# MM32F3270 register map
File version: 3.01
CPU: CM3 r2p1, selectable endian, MPU, no FPU, 3 interrupt priority bits
Registers are 32-bit, read-write, reset 0x0 unless marked. A register's access mark holds for its fields unless they carry their own. Offsets are from the block's base; [hi:lo] are bit positions; lines under a group give offsets from that group; {n}, {i} and the like mark numbered series.

## CAN — Controller area network
Base 0x40006400
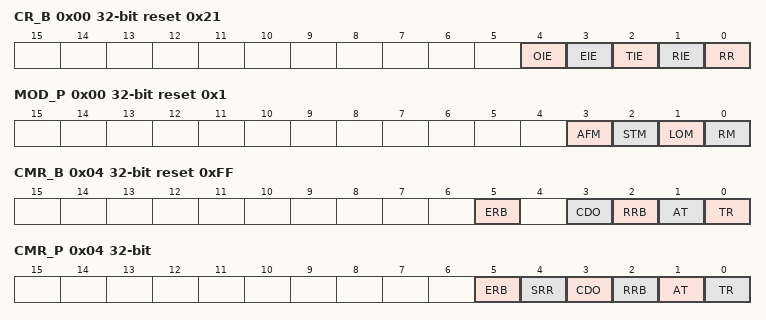
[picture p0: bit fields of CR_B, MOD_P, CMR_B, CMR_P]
0x00 CR_B reset 0x21 — Basic control register
  [4] OIE — Overflow interrupt enable
  [3] EIE — Error interrupt enable
  [2] TIE — Transmit interrupt enable
  [1] RIE — Receive interrupt enable
  [0] RR — Reset request
0x00 MOD_P reset 0x1 (alternate view of CR_B) — Peli Mode register
  [3] AFM — Acceptance filter mode
  [2] STM — Self test mode
  [1] LOM — Listen only mode
  [0] RM — Reset mode
0x04 CMR_B wo reset 0xFF — Basic Command register
  [5] ERB — Empty Rxbuffer
  [3] CDO — Clear data overrun
  [2] RRB — Release receive buffer
  [1] AT — Abort transmission
  [0] TR — Transmission request
0x04 CMR_P wo (alternate view of CMR_B) — Peli Command register
  [5] ERB — Empty Rxbuffer
  [4] SRR — Self reset request
  [3] CDO — Clear data overrun
  [2] RRB — Release receive buffer
  [1] AT — Abort transmission
  [0] TR — Transmission request
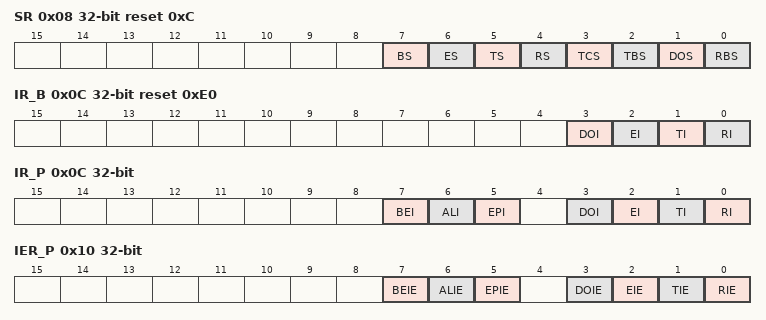
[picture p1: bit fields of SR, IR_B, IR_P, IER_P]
0x08 SR reset 0xC — Status register
  [7] BS — Bus status
  [6] ES — Error status
  [5] TS — Transmit status
  [4] RS — Receive status
  [3] TCS — Transmission complete status
  [2] TBS — Transmit buffer status
  [1] DOS — Data overrun status
  [0] RBS — Receive buffer status
0x0C IR_B ro reset 0xE0 — Interrupt register
  [3] DOI — Data overrun interrupt
  [2] EI — Error interrupt
  [1] TI — Transmit interrupt
  [0] RI — Receive interrupt
0x0C IR_P ro (alternate view of IR_B) — Interrupt register
  [7] BEI — Bus error interrupt
  [6] ALI — Arbitration lost interrupt
  [5] EPI — Error passive interrupt
  [3] DOI — Data overrun interrupt
  [2] EI — Error interrupt
  [1] TI — Transmit interrupt
  [0] RI — Receive interrupt
0x10 GROUP0_ACR_B — Basic Acceptance Code register
  [7:0] AC — Acceptance code
0x10 IER_P (alternate view of GROUP0_ACR_B) — Peli Interrupt Enable register
  [7] BEIE — Bus error interrupt enable
  [6] ALIE — Arbitration lost interrupt enable
  [5] EPIE — Error passive interrupt enable
  [3] DOIE — Data overrun interrupt enable
  [2] EIE — Error interrupt enable
  [1] TIE — Transmit interrupt enable
  [0] RIE — Receive interrupt enable
0x14 GROUP0_AMR_B — Basic Acceptance Mask register
  [7:0] AM — Acceptance mask
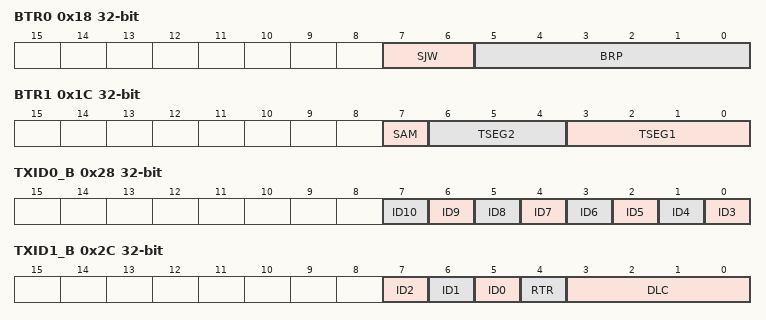
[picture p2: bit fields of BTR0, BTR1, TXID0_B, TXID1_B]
0x18 BTR0 — Bus Timing register 0
  [7:6] SJW — Synchronization jump width
  [5:0] BRP — Baud rate prescaler
0x1C BTR1 — Bus Timing register 1
  [7] SAM — Sampling
  [6:4] TSEG2 — Time segment 2
  [3:0] TSEG1 — Time segment 1
0x28 TXID0_B — Basic TX ID register 0
  [n-3] ID{n} (n=3..10) — Identifier bit {n}
0x2C TXID1_B — Basic TX ID register 1
  [7] ID2 — Identifier bit 2
  [6] ID1 — Identifier bit 1
  [5] ID0 — Identifier bit 0
  [4] RTR — Remote transmission request
  [3:0] DLC — Data length code
0x2C ALC_P (alternate view of TXID1_B) — Peli Arbitration Lost Capture register
  [4:0] BITNO — Bit number
0x30 TXDR0_B — Basic TX Data register 0
  [31:0] TXDR0 — Transmit data register
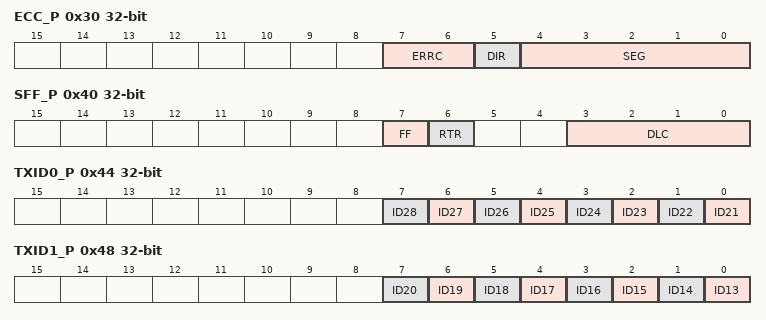
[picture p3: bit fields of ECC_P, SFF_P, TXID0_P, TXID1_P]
0x30 ECC_P ro (alternate view of TXDR0_B) — Peli Error Code Capture register
  [7:6] ERRC — Error code
  [5] DIR — Direction
  [4:0] SEG
0x34 TXDR1_B — Basic TX Data register 1
  [31:0] TXDR1 — Transmit data register
0x34 EWLR_P reset 0x60 (alternate view of TXDR1_B) — Peli Error Warning Limit register
  [7:0] EWL — Programmable error warning limit
0x38 TXDR2_B — Basic Send Data register 2
  [31:0] TXDR2 — Transmit data register
0x38 RXERR_P (alternate view of TXDR2_B) — Peli RX Error Counter register
  [7:0] RXERR — RX error counter register
{0x30+4i} TXDR{i}_B (i=3..7) — Basic TX Data register {i}
  [31:0] TXDR{i} — Transmit data register
0x3C TXERR_P (alternate view of TXDR3_B) — Peli TX Error Counter register
  [7:0] TXERR — TX error counter register
0x40 SFF_P (alternate view of TXDR4_B) — Peli Send Frame Format register
  [7] FF — Frame format
  [6] RTR — Remote transmission request
  [3:0] DLC — Data length code bit
0x40 GROUP0_ACR0_P (alternate view of SFF_P) — Peli Acceptance Code register 0
  [7:0] AC — Acceptance code
0x44 TXID0_P (alternate view of TXDR5_B) — Peli TX ID register 0
  [n-21] ID{n} (n=21..28) — Identifier bit {n}
0x44 GROUP0_ACR1_P (alternate view of TXID0_P) — Peli Acceptance Code register 1
  [7:0] AC — Acceptance code
0x48 TXID1_P (alternate view of TXDR6_B) — Peli TX ID register 1
  [n-13] ID{n} (n=13..20) — Identifier bit {n}
0x48 GROUP0_ACR2_P (alternate view of TXID1_P) — Peli Acceptance Code register 2
  [7:0] AC — Acceptance code
0x4C TXDATA0_P (alternate view of TXDR7_B) — Peli TX Data register 0
  [7:0] DATA0
0x4C GROUP0_ACR3_P (alternate view of TXDATA0_P) — Peli Acceptance Code register 3
  [7:0] AC — Acceptance code
{0x4C+4i} TXDATA{i}_P (i=1..9) — Peli TX Data register {i}
  [7:0] DATA{i}
{0x50+4i} GROUP0_AMR{i}_P (alternate view of TXDATA{i+1}_P) (i=0..3) — Peli Acceptance Mask register {i}
  [7:0] AM — Acceptance mask
0x7C CDR — Clock Divider register
  [7] MODE — CAN mode
0x80 AFM0 — Filter Mode register 0
  [7:1] AFM_7_1 — Acceptance filter mode
0x84 AFM1 — Filter Mode register 1
  [7:0] AFM_15_8 — Acceptance filter mode
0x88 AFM2 — Filter Mode register 2
  [3:0] AFM_19_16 — Acceptance filter mode
0x8C FGA0 — Filter Group Enable Register 0
  [7:0] FGA_7_0 — Filter group enable
0x90 FGA1 — Filter Group Enable Register 1
  [7:0] FGA_15_8 — Filter group enable
0x94 FGA2 — Filter Group Enable Register 2
  [3:0] FGA_19_16 — Filter group enable
{0x78+0x20*i} GROUP{i}_ACR_B (i=1..19) — Basic Acceptance Code register
  [7:0] AC — Acceptance code
0x98 GROUP1_ACR0_P (alternate view of GROUP1_ACR_B) — Peli Acceptance Code register0
  [7:0] AC — Acceptance code
{0x7C+0x20*i} GROUP{i}_ACR1_P (i=1..19) — Peli Acceptance Code register1
  [7:0] AC — Acceptance code
{0x80+0x20*i} GROUP{i}_ACR2_P (i=1..19) — Peli Acceptance Code register2
  [7:0] AC — Acceptance code
{0x84+0x20*i} GROUP{i}_ACR3_P (i=1..19) — Peli Acceptance Code register3
  [7:0] AC — Acceptance code
{0x88+0x20*i} GROUP{i}_AMR_B (i=1..19) — Basic Acceptance Mask register
  [7:0] AM — Acceptance mask
{0x88+0x20*i} GROUP{i}_AMR0_P (alternate view of GROUP{i}_AMR_B) (i=1..19) — Peli Acceptance Mask register 0
  [7:0] AM — Acceptance mask
{0x8C+0x20*i} GROUP{i}_AMR1_P (i=1..19) — Peli Acceptance Mask register 1
  [7:0] AM — Acceptance mask
{0x90+0x20*i} GROUP{i}_AMR2_P (i=1..19) — Peli Acceptance Mask register 2
  [7:0] AM — Acceptance mask
{0x94+0x20*i} GROUP{i}_AMR3_P (i=1..19) — Peli Acceptance Mask register 3
  [7:0] AM — Acceptance mask
0xB8 GROUP2_ACR0_P (alternate view of GROUP2_ACR_B) — Peli Acceptance Code register
  [7:0] AC — Acceptance code
0xD8 GROUP3_ACR0_P (alternate view of GROUP3_ACR_B) — Peli Acceptance Code register0
  [7:0] AC — Acceptance code
0xF8 GROUP4_ACR0_P (alternate view of GROUP4_ACR_B) — Peli Acceptance Code register
  [7:0] AC — Acceptance code
0x118 GROUP5_ACR0_P (alternate view of GROUP5_ACR_B) — Peli Acceptance Code register0
  [7:0] AC — Acceptance code
0x138 GROUP6_ACR0_P (alternate view of GROUP6_ACR_B) — Peli Acceptance Code register
  [7:0] AC — Acceptance code
0x158 GROUP7_ACR0_P (alternate view of GROUP7_ACR_B) — Peli Acceptance Code register0
  [7:0] AC — Acceptance code
0x178 GROUP8_ACR0_P (alternate view of GROUP8_ACR_B) — Peli Acceptance Code register
  [7:0] AC — Acceptance code
0x198 GROUP9_ACR0_P (alternate view of GROUP9_ACR_B) — Peli Acceptance Code register0
  [7:0] AC — Acceptance code
0x1B8 GROUP10_ACR0_P (alternate view of GROUP10_ACR_B) — Peli Acceptance Code register
  [7:0] AC — Acceptance code
0x1D8 GROUP11_ACR0_P (alternate view of GROUP11_ACR_B) — Peli Acceptance Code register0
  [7:0] AC — Acceptance code
0x1F8 GROUP12_ACR0_P (alternate view of GROUP12_ACR_B) — Peli Acceptance Code register
  [7:0] AC — Acceptance code
0x218 GROUP13_ACR0_P (alternate view of GROUP13_ACR_B) — Peli Acceptance Code register0
  [7:0] AC — Acceptance code
0x238 GROUP14_ACR0_P (alternate view of GROUP14_ACR_B) — Peli Acceptance Code register
  [7:0] AC — Acceptance code
0x258 GROUP15_ACR0_P (alternate view of GROUP15_ACR_B) — Peli Acceptance Code register0
  [7:0] AC — Acceptance code
0x278 GROUP16_ACR0_P (alternate view of GROUP16_ACR_B) — Peli Acceptance Code register
  [7:0] AC — Acceptance code
{0x78+0x20*i} GROUP{i}_ACR0_P (alternate view of GROUP{i}_ACR_B) (i=17..19) — Peli Acceptance Code register0
  [7:0] AC — Acceptance code
